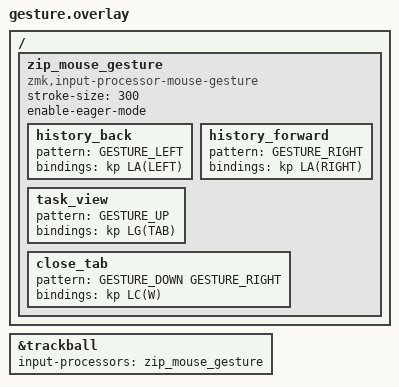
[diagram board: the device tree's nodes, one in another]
&trackball {
    input-processors = <&zip_mouse_gesture>;
};

/ {
    zip_mouse_gesture: zip_mouse_gesture {
        compatible = "zmk,input-processor-mouse-gesture";

        stroke-size = <300>;
        enable-eager-mode;

        history_back {
            pattern = <GESTURE_LEFT>;
            bindings = <&kp LA(LEFT)>;
        };

        history_forward {
            pattern = <GESTURE_RIGHT>;
            bindings = <&kp LA(RIGHT)>;
        };

        task_view {
            pattern = <GESTURE_UP>;
            bindings = <&kp LG(TAB)>;
        };

        close_tab {
            pattern = <GESTURE_DOWN GESTURE_RIGHT>;
            bindings = <&kp LC(W)>;
        };
    };
};
